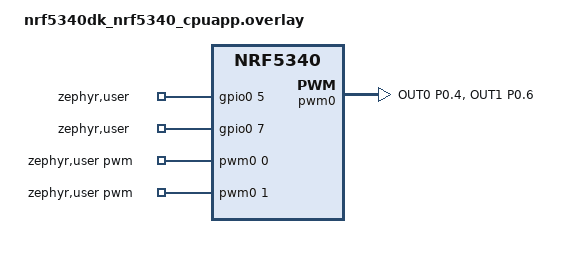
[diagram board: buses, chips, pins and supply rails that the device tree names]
/*
 * Copyright (c) 2026 Nordic Semiconductor ASA
 *
 * SPDX-License-Identifier: Apache-2.0
 */

/* Test requires wire connection between:
 *  - PWM22 OUT[0] at P0.04 <-> GPIO input at P0.05
 *  - PWM22 OUT[1] at P0.06 <-> GPIO input at P0.07
 */

/ {
	zephyr,user {
		pwms = <&pwm0 0 16000000 PWM_POLARITY_NORMAL>,
		       <&pwm0 1 16000000 PWM_POLARITY_NORMAL>;

		gpios = <&gpio0 5 GPIO_ACTIVE_HIGH>,
			<&gpio0 7 GPIO_ACTIVE_HIGH>;
	};
};

&pinctrl {
	pwm0_alt: pwm0_alt {
		group1 {
			psels = <NRF_PSEL(PWM_OUT0, 0, 4)>,
				<NRF_PSEL(PWM_OUT1, 0, 6)>;
		};
	};

	pwm0_alt_sleep: pwm0_alt_sleep {
		group1 {
			psels = <NRF_PSEL(PWM_OUT0, 0, 4)>,
				<NRF_PSEL(PWM_OUT1, 0, 6)>;
			low-power-enable;
		};
	};
};

&gpio0 {
	status = "okay";
};

&pwm0 {
	pinctrl-0 = <&pwm0_alt>;
	pinctrl-1 = <&pwm0_alt_sleep>;
	pinctrl-names = "default", "sleep";
	status = "okay";
};
